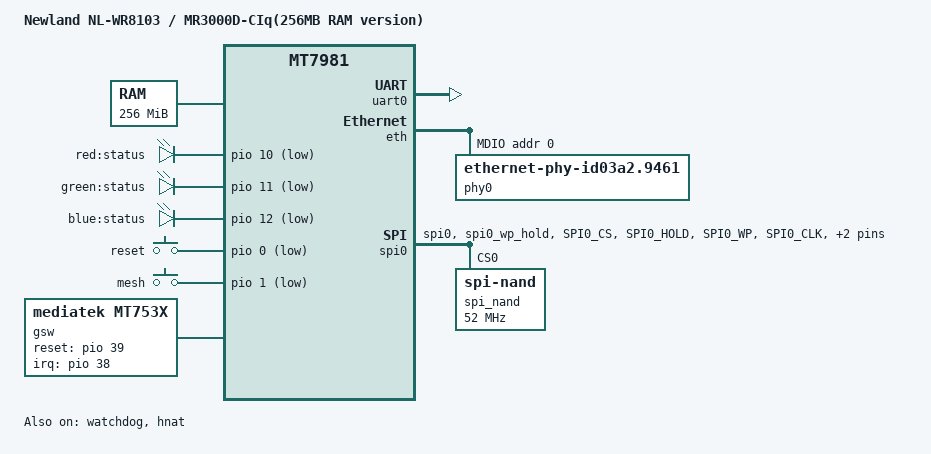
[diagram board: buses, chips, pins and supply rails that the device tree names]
/dts-v1/;
#include <dt-bindings/gpio/gpio.h>
#include <dt-bindings/input/input.h>
#include "mt7981.dtsi"

/ {
        model = "Newland NL-WR8103 / MR3000D-CIq(256MB RAM version)";
        compatible = "newland,nl-wr8103", "mediatek,mt7981";

	aliases {
		led-boot = &status_red_led;
		led-failsafe = &status_red_led;
		led-running = &status_blue_led;
		led-upgrade = &status_green_led;
	};

	chosen {
		bootargs = "console=ttyS0,115200n1 loglevel=8  \
				earlycon=uart8250,mmio32,0x11002000";
	};

        memory {
                reg = <0 0x40000000 0 0x10000000>;
        };

        leds {
                compatible = "gpio-leds";

                status_red_led: led-0 {
                        label = "red:status";
                        gpios = <&pio 10 GPIO_ACTIVE_LOW>;
                };

                status_green_led: led-1 {
                        label = "green:status";
                        gpios = <&pio 11 GPIO_ACTIVE_LOW>;
                };

                status_blue_led: led-2 {
                        label = "blue:status";
                        gpios = <&pio 12 GPIO_ACTIVE_LOW>;
                };

        };

        gpio-keys {
                compatible = "gpio-keys";
                        button-reset {
                                label = "reset";
                                linux,code = <KEY_RESTART>;
                                gpios = <&pio 0 GPIO_ACTIVE_LOW>;
                        };

                        button-mesh {
                                label = "mesh";
                                gpios = <&pio 1 GPIO_ACTIVE_LOW>;
				linux,code = <BTN_9>;
				linux,input-type = <EV_SW>;
                        };
        };

        gsw: gsw@0 {
                compatible = "mediatek,mt753x";
                mediatek,ethsys = <&ethsys>;
                #address-cells = <1>;
                #size-cells = <0>;
        };

	nmbm_spim_nand {
                compatible = "generic,nmbm";
                #address-cells = <1>;
                #size-cells = <1>;

                lower-mtd-device = <&spi_nand>;
                forced-create;

                partitions {
                        compatible = "fixed-partitions";
                        #address-cells = <1>;
                        #size-cells = <1>;

                        partition@0 {
                                label = "BL2";
                                reg = <0x00 0x100000>;
                        };

                        partition@100000 {
                                label = "u-boot-env";
                                reg = <0x100000 0x80000>;
                        };

                        partition@180000 {
                                label = "Factory";
                                reg = <0x180000 0x200000>;
                        };

                        partition@380000 {
                                label = "FIP";
                                reg = <0x380000 0x200000>;
                        };

			partition@580000 {
				label = "ubi";
				reg = <0x580000 0x7200000>;
			};
                };
        };
};

&uart0 {
        status = "okay";
};

&watchdog {
        status = "okay";
};
  
&eth {
    status = "okay";

    gmac0: mac@0 {
        compatible = "mediatek,eth-mac";
        reg = <0>;
        phy-mode = "2500base-x";

        fixed-link {
            speed = <2500>;
            full-duplex;
            pause;
        };
    };

    gmac1: mac@1 {
        compatible = "mediatek,eth-mac";
        reg = <1>;
        phy-mode = "gmii";
        phy-handle = <&phy0>;
    };

    mdio: mdio-bus {
		#address-cells = <1>;
		#size-cells = <0>;

		phy0: ethernet-phy@0 {
			compatible = "ethernet-phy-id03a2.9461";
			reg = <0>;
			phy-mode = "gmii";
			nvmem-cells = <&phy_calibration>;
			nvmem-cell-names = "phy-cal-data";
		};
	};
};

&gsw {
        mediatek,mdio = <&mdio>;
        mediatek,mdio_master_pinmux = <0>;
        reset-gpios = <&pio 39 0>;
        interrupt-parent = <&pio>;
        interrupts = <38 IRQ_TYPE_LEVEL_HIGH>;
        status = "okay";

	port6: port@6 {
		compatible = "mediatek,mt753x-port";
		mediatek,ssc-on;
		reg = <6>;
		phy-mode = "sgmii";

                fixed-link {
                        speed = <2500>;
                        full-duplex;
                };
        };
};

&hnat {
        mtketh-wan = "eth1";
        mtketh-lan = "eth0";
        mtketh-max-gmac = <2>;
        status = "okay";
};

&spi0 {
        pinctrl-names = "default";
        pinctrl-0 = <&spi0_flash_pins>;
        status = "okay";

        spi_nand: spi_nand@0 {
                #address-cells = <1>;
                #size-cells = <1>;
                compatible = "spi-nand";
                reg = <0>;
                spi-max-frequency = <52000000>;
                spi-tx-bus-width = <4>;
                spi-rx-bus-width = <4>;
                spi-cal-enable;
                spi-cal-mode = "read-data";
                spi-cal-datalen = <7>;
                spi-cal-data = /bits/ 8 <0x53 0x50 0x49 0x4E 0x41 0x4E 0x44>; /* 'SPINAND' */
                spi-cal-addrlen = <5>;
                spi-cal-addr = /bits/ 32 <0x0 0x0 0x0 0x0 0x0>;
        };
};

&pio {
	spi0_flash_pins: spi0-pins {
		mux {
			function = "spi";
			groups = "spi0", "spi0_wp_hold";
		};

		conf-pu {
			pins = "SPI0_CS", "SPI0_HOLD", "SPI0_WP";
			drive-strength = <MTK_DRIVE_8mA>;
			bias-pull-up = <MTK_PUPD_SET_R1R0_11>;
		};

		conf-pd {
			pins = "SPI0_CLK", "SPI0_MOSI", "SPI0_MISO";
			drive-strength = <MTK_DRIVE_8mA>;
			bias-pull-down = <MTK_PUPD_SET_R1R0_11>;
		};
	};
};
